# RS1xxxx register map
Vendor: Silicon Lab Inc.; Series: ARMCM4; File version: 1.2
CPU: CM4 r1p0, little endian, MPU, FPU, 6 interrupt priority bits
Registers are 32-bit, read-write, reset 0x0 unless marked. A register's access mark holds for its fields unless they carry their own. Offsets are from the block's base; [hi:lo] are bit positions.

## ULP_SSI — Synchronous Serial Interface(SSI)
Base 0x24040800
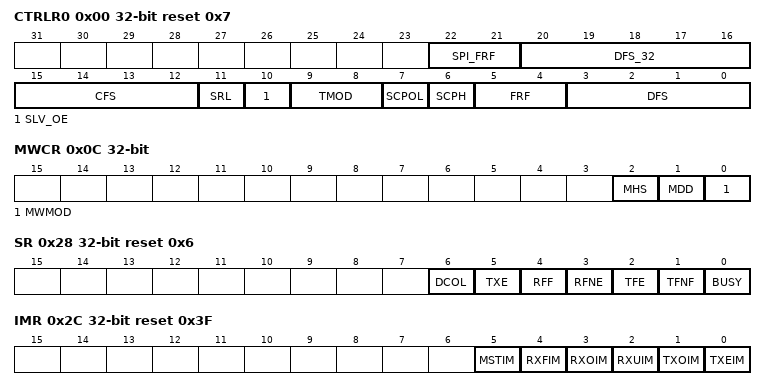
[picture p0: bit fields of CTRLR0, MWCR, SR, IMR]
0x00 CTRLR0 reset 0x7 (reset mask 0xFFFF) — Control Register 0
  [22:21] SPI_FRF — Selects data frame format for transmitting or receiving data
    0=Standard SPI Format; 1=Dual SPI Format; 2=Quad SPI Format; 3=Reser
  [20:16] DFS_32 — Selects the data frame length
    3=None (Range -> 3 bit); 15=none (Range -> 16 bit)
  [15:12] CFS — Control Frame Size Selects the length of the control word for the Micro wire frame format
    0=None (Range -> 1 bit); 15=none (Range -> 16 bit)
  [11] SRL — Shift Register Loop Used for testing purposes only
    0=None (Normal Mode Operation); 1=none (Test Mode Operation)
  [10] SLV_OE — DW_apb_ssi is configured as a serial-slave device
    0=None (Slave txd is enabled); 1=none (Slave txd is disabled)
  [9:8] TMOD — Selects the mode of transfer for serial communication
    0=Transmit and Receive; 1=Transmit Only; 2=Receive Only
  [7] SCPOL — Serial Clock Polarity. Valid when the frame format (FRF) is set to Motorola SPI
    0=disable (Inactive state of serial clock is low); 1=enable (Inactive state of serial clock is high)
  [6] SCPH — Serial Clock Phase. Valid when the frame format (FRF) is set to Motorola SPI
    0=disable (Serial clock toggles in middle of first data bit); 1=enable (Serial clock toggles at start of first data bit)
  [5:4] FRF — Frame Format, Selects which serial protocol transfers the data
    0=Motorola SPI; 1=Texas Instruments SSP; 2=National Semiconductors Micro wire; 3=none
  [3:0] DFS range 0..16 — Select the data frame length (4-bit to 16-bit serial data transfers)
0x04 CTRLR1 — Control Register 1
  [15:0] NDF — Number of Data Frames.When TMOD = 10 or TMOD = 11, this register field sets the number of data frames to be continuously received by the ssi_master
0x08 SSIENR — SSI Enable Register
  [0] SSI_EN — Enables and disables all ssi operations
0x0C MWCR — Micro wire Control Register
  [2] MHS — Microwire Handshaking. Used to enable and disable the busy/ready handshaking interface for the Microwire protocol
    0=disable (handshaking interface is disabled); 1=enable (handshaking interface is enabled)
  [1] MDD — The direction of the data word when the Micro wire serial protocol is used
    0=disable (the data word is received by the SSI MacroCell from the external serial device); 1=enable (the data word is transmitted from the SSI MacroCell to the external serial device)
  [0] MWMOD — The Micro wire transfer is sequential or non-sequential
    0=disable (non-sequential transfer); 1=enable (sequential transfer)
0x10 SER — SLAVE ENABLE REGISTER
  [3:0] SER — Each bit in this register corresponds to a slave select line (ss_x_n) from the SSI master.
    0=disable (Not selected); 1=enable (selected)
0x14 BAUDR — Baud Rate Select Register
  [15:0] SCKDV — SSI Clock Divider.The LSB for this field is always set to 0 and is unaffected by a write operation, which ensures an even value is held in this register
0x18 TXFTLR — Transmit FIFO Threshold Level Register
  [3:0] TFT — Controls the level of entries (or below) at which the transmit FIFO controller triggers an interrupt
0x1C RXFTLR — Receive FIFO Threshold Level
  [3:0] RFT — Controls the level of entries (or above) at which the receive FIFO controller triggers an interrupt
0x20 TXFLR ro — Transmit FIFO Level Register
  [4:0] TXTFL — Contains the number of valid data entries in the transmit FIFO
0x24 RXFLR ro — Receive FIFO Level Register
  [4:0] RXTFL — Contains the number of valid data entries in the receive FIFO
0x28 SR ro reset 0x6 — Status Register
  [6] DCOL — This bit is set if the ss_in_n input is asserted by another master, while the ssi master is in the middle of the transfer
    0=disable (No error); 1=enable (Transmit data collision error)
  [5] TXE — This bit is cleared when read
    0=disable (No error); 1=enable (Transmission error)
  [4] RFF — When the receive FIFO is completely full this bit is set
    0=disable (Receive FIFO is not full); 1=enable (Receive FIFO is full)
  [3] RFNE — Set when the receive FIFO contains one or more entries and is cleared when the receive FIFO is empty
    0=disable (Receive FIFO is empty); 1=enable (Receive FIFO is not empty)
  [2] TFE — When the transmit FIFO is completely empty this bit is set
    0=disable (Transmit FIFO is not empty); 1=enable (Transmit FIFO is empty)
  [1] TFNF — Set when the transmit FIFO contains one or more empty locations and is cleared when the FIFO is full
    0=disable (Transmit FIFO is full); 1=enable (Transmit FIFO is not full)
  [0] BUSY — indicates that a serial transfer is in progress
    0=disable (SSI is idle or disabled); 1=enable (SSI is actively transferring data)
0x2C IMR reset 0x3F — Interrupt Mask Register
  [5] MSTIM — Multi-Master Contention Interrupt Mask
    0=disable (ssi_mst_intr interrupt is masked); 1=enable (ssi_mst_intr interrupt is not masked)
  [4] RXFIM — Receive FIFO Full Interrupt Mask
    0=disable (ssi_rxf_intr interrupt is masked); 1=enable (ssi_rxf_intr interrupt is not masked)
  [3] RXOIM — Receive FIFO Overflow Interrupt Mask
    0=disable (ssi_rxo_intr interrupt is masked); 1=enable (ssi_rxo_intr interrupt is not masked)
  [2] RXUIM — Receive FIFO Underflow Interrupt Mask
    0=disable (ssi_rxu_intr interrupt is masked); 1=enable (ssi_rxu_intr interrupt is not masked)
  [1] TXOIM — Transmit FIFO Overflow Interrupt Mask
    0=disable (ssi_txo_intr interrupt is masked); 1=enable (ssi_txo_intr interrupt is not masked)
  [0] TXEIM — Transmit FIFO Empty Interrupt Mask
    0=disable (ssi_txe_intr interrupt is masked); 1=enable (ssi_txe_intr interrupt is not masked)
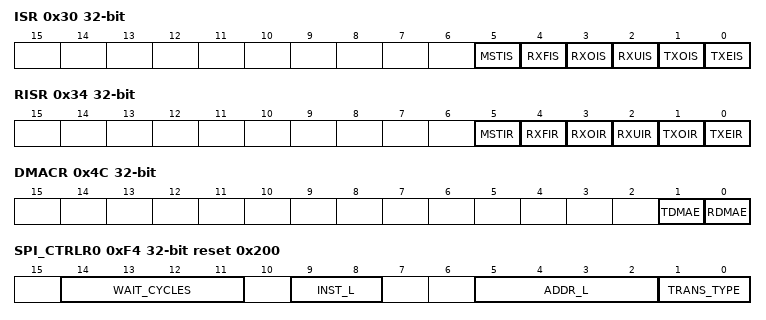
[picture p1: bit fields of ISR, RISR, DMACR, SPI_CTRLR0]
0x30 ISR ro — Interrupt Status Register
  [5] MSTIS — Multi-Master Contention Interrupt Status
    0=disable (ssi_mst_intr interrupt not active after masking); 1=enable (ssi_mst_intr interrupt is active after masking)
  [4] RXFIS — Receive FIFO Full Interrupt Status
    0=disable (ssi_rxf_intr interrupt is not active after masking); 1=enable (ssi_rxf_intr interrupt is full after masking)
  [3] RXOIS — Receive FIFO Overflow Interrupt Status
    0=disable (ssi_rxo_intr interrupt is not active after masking); 1=enable (ssi_rxo_intr interrupt is active after masking)
  [2] RXUIS — Receive FIFO Underflow Interrupt Status
    0=disable (ssi_rxu_intr interrupt is not active after masking); 1=enable (ssi_rxu_intr interrupt is active after masking)
  [1] TXOIS — Transmit FIFO Overflow Interrupt Status
    0=disable (ssi_txo_intr interrupt is not active after masking); 1=enable (ssi_txo_intr interrupt is active after masking)
  [0] TXEIS — Transmit FIFO Empty Interrupt Status
    0=disable (ssi_txe_intr interrupt is not active after masking); 1=enable (ssi_txe_intr interrupt is active after masking)
0x34 RISR ro — Raw Interrupt Status Register
  [5] MSTIR — Multi-Master Contention Raw Interrupt Status
    0=disable (ssi_mst_intr interrupt is not active prior to masking); 1=enable (ssi_mst_intr interrupt is active prior masking)
  [4] RXFIR — Receive FIFO Full Raw Interrupt Status
    0=disable (ssi_rxf_intr interrupt is not active prior to masking); 1=enable (ssi_rxf_intr interrupt is active prior to masking)
  [3] RXOIR — Receive FIFO Overflow Raw Interrupt Status
    0=disable (ssi_rxo_intr interrupt is not active prior to masking); 1=enable (ssi_rxo_intr interrupt is active prior masking)
  [2] RXUIR — Receive FIFO Underflow Raw Interrupt Status
    0=disable (ssi_rxu_intr interrupt is not active prior to masking); 1=enable (ssi_rxu_intr interrupt is active prior to masking)
  [1] TXOIR — Transmit FIFO Overflow Raw Interrupt Status
    0=disable (ssi_txo_intr interrupt is not active prior to masking); 1=enable (1 = ssi_txo_intr interrupt is active prior masking)
  [0] TXEIR — Transmit FIFO Empty Raw Interrupt Status
    0=disable (ssi_txe_intr interrupt is not active prior to masking); 1=enable (ssi_txe_intr interrupt is active prior masking)
0x38 TXOICR ro — Transmit FIFO Overflow Interrupt Clear Register
  [0] TXOICR — Clear Transmit FIFO Overflow Interrupt This register reflects the status of the interrupt
0x3C RXOICR ro — Receive FIFO Overflow Interrupt Clear Register
  [0] RXOICR — This register reflects the status of the interrupt A read from this register clears the ssi_rxo_intr interrupt
0x40 RXUICR ro — Receive FIFO Underflow Interrupt Clear Register
  [0] RXUICR — This register reflects the status of the interrupt A read from this register clears the ssi_rxu_intr interrupt
0x44 MSTICR ro — Multi-Master Interrupt Clear Register
  [0] MSTICR — This register reflects the status of the interrupt A read from this register clears the ssi_mst_intr interrupt
0x48 ICR ro — Interrupt Clear Register
  [0] ICR — This register is set if any of the interrupts below are active A read clears the ssi_txo_intr, ssi_rxu_intr, ssi_rxo_intr, and the ssi_mst_intr interrupts
0x4C DMACR — DMA Control Register
  [1] TDMAE — This bit enables/disables the transmit FIFO DMA channel
    0=disabled (Transmit DMA disabled); 1=enabled (Transmit DMA enabled)
  [0] RDMAE — This bit enables/disables the receive FIFO DMA channel
    0=disabled (Receive DMA disabled); 1=enabled (Receive DMA enabled)
0x50 DMATDLR — DMA Transmit Data Level
  [3:0] DMATDL — This bit field controls the level at which a DMA request is made by the transmit logic
0x54 DMARDLR — DMA Receive Data Level Register
  [3:0] DMARDL — This bit field controls the level at which a DMA request is made by the receive logic
0x58 IDR ro reset 0xFFFFFFFF — Identification Register
  [31:0] IDCODE — This register contains the peripherals identification code
0x5C SSI_COMP_VERSION ro reset 0x3430302A — coreKit version ID register
  [31:0] SSI_COMP_VERSION — Contains the hex representation of the Synopsys component version
0x60 DR (reset mask 0xFFFF) — Data Register
  [31:0] DR — When writing to this register must right-justify the data
0xF0 RX_SAMPLE_DLY — Rx Sample Delay Register
  [7:0] RSD — Receive Data (rxd) Sample Delay. This register is used to delay the sample of the rxd input signal.
0xF4 SPI_CTRLR0 reset 0x200 — SPI control Register
  [14:11] WAIT_CYCLES — This bit defines the wait cycles in dual/quad mode between control frames transmit and data reception, Specified as number of SPI clock cycles
  [9:8] INST_L — DUAL/QUAD length in bits
  [5:2] ADDR_L — This bit defines length of address to be transmitted, The transfer begins only after these many bits are programmed into the FIFO
  [1:0] TRANS_TYPE — Address and instruction transfer format
